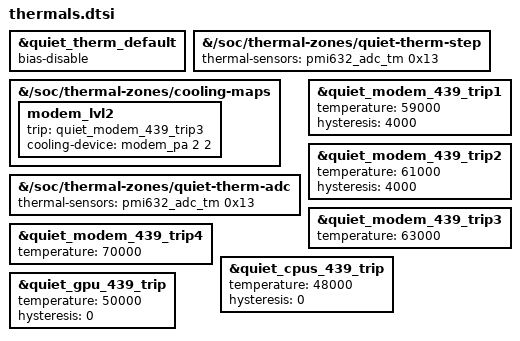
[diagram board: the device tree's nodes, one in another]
&quiet_therm_default {
    bias-disable;
};

&{/soc/thermal-zones/quiet-therm-step} {
    /delete-property/ wake-capable-sensor;
    thermal-sensors = <&pmi632_adc_tm 0x13>;
};

&{/soc/thermal-zones/cooling-maps} {
    /delete-node/ battery_lvl6;
    /delete-node/ battery_lvl7;

    modem_lvl2 {
        trip = <&quiet_modem_439_trip3>;
        cooling-device = <&modem_pa 2 2>;
    };
};

&{/soc/thermal-zones/quiet-therm-adc} {
    thermal-sensors = <&pmi632_adc_tm 0x13>;
};

&quiet_modem_439_trip1 {
    temperature = <59000>;
    hysteresis = <4000>;
};

&quiet_modem_439_trip2 {
    temperature = <61000>;
    hysteresis = <4000>;
};

&quiet_modem_439_trip3 {
    temperature = <63000>;
};

&quiet_modem_439_trip4 {
    temperature = <70000>;
};

&quiet_cpus_439_trip {
    temperature = <48000>;
    hysteresis = <0>;
};

&quiet_gpu_439_trip {
    temperature = <50000>;
    hysteresis = <0>;
};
